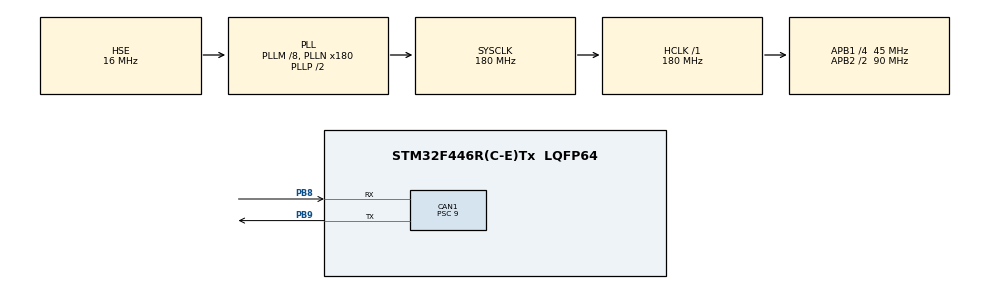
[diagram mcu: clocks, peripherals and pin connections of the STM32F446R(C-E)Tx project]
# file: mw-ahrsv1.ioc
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CAN1.BS1=CAN_BS1_3TQ
CAN1.CalculateBaudRate=1000000
CAN1.CalculateTimeBit=1000.00
CAN1.CalculateTimeQuantum=200.0
CAN1.Prescaler=9
Mcu.Family=STM32F4
Mcu.Name=STM32F446R(C-E)Tx
Mcu.Package=LQFP64
NVIC.CAN1_RX0_IRQn=true\:0\:0\:false\:false\:true\:true\:true
NVIC.PriorityGroup=NVIC_PRIORITYGROUP_4
PA13.Signal=SYS_JTMS-SWDIO
PA14.Signal=SYS_JTCK-SWCLK
PB8.Mode=CAN_Activate
PB8.Signal=CAN1_RX
PB9.Mode=CAN_Activate
PB9.Signal=CAN1_TX
PH0-OSC_IN.Mode=HSE-External-Oscillator
PH0-OSC_IN.Signal=RCC_OSC_IN
PH1-OSC_OUT.Mode=HSE-External-Oscillator
PH1-OSC_OUT.Signal=RCC_OSC_OUT
ProjectManager.HeapSize=0x200
ProjectManager.StackSize=0x400
ProjectManager.TargetToolchain=STM32CubeIDE
RCC.AHBFreq_Value=180000000
RCC.APB1CLKDivider=RCC_HCLK_DIV4
RCC.APB1Freq_Value=45000000
RCC.APB1TimFreq_Value=90000000
RCC.APB2CLKDivider=RCC_HCLK_DIV2
RCC.APB2Freq_Value=90000000
RCC.APB2TimFreq_Value=180000000
RCC.CortexFreq_Value=180000000
RCC.HCLKFreq_Value=180000000
RCC.HSE_VALUE=16000000
RCC.PLLM=8
RCC.PLLN=180
RCC.PLLSourceVirtual=RCC_PLLSOURCE_HSE
RCC.SYSCLKFreq_VALUE=180000000
RCC.SYSCLKSource=RCC_SYSCLKSOURCE_PLLCLK
RCC.USBFreq_Value=180000000
RCC.VCOOutputFreq_Value=360000000
board=custom

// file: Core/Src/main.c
/* USER CODE BEGIN Header */
/**
  ******************************************************************************
  * @file           : main.c
  * @brief          : Main program body
  ******************************************************************************
  * @attention
  *
  * <h2><center>&copy; Copyright (c) 2021 STMicroelectronics.
  * All rights reserved.</center></h2>
  *
  * This software component is licensed by ST under BSD 3-Clause license,
  * the "License"; You may not use this file except in compliance with the
  * License. You may obtain a copy of the License at:
  *                        opensource.org/licenses/BSD-3-Clause
  *
  ******************************************************************************
  */
/* USER CODE END Header */
#include "main.h"
#include "MW-AHRSv1.h"

/* USER CODE BEGIN Includes */
#define AX_WRITE_DATA  3
/* USER CODE END Includes */

/* USER CODE BEGIN PTD */

CAN_RxHeaderTypeDef txheader;
CAN_RxHeaderTypeDef rxheader;

MW_AHRS ahrs_obj = {0, };

/* USER CODE END PTD */

CAN_HandleTypeDef hcan1;

void SystemClock_Config(void);
static void MX_GPIO_Init(void);
static void MX_CAN1_Init(void);
/* USER CODE BEGIN PFP */

void can_init_user(void);
void mw_ahrsv1_trans(void);

uint8_t sendData[100] = { 0, };

float yaw_data;
float roll_data;
float pitch_data;

/* USER CODE END PFP */

int main(void)
{

  /* MCU Configuration--------------------------------------------------------*/

  /* Reset of all peripherals, Initializes the Flash interface and the Systick. */
  HAL_Init();

  /* Configure the system clock */
  SystemClock_Config();

  /* Initialize all configured peripherals */
  MX_GPIO_Init();
  MX_CAN1_Init();
  /* USER CODE BEGIN 2 */

   can_init_user();

   HAL_CAN_ActivateNotification(&hcan1, CAN_IT_TX_MAILBOX_EMPTY | CAN_IT_RX_FIFO0_MSG_PENDING | CAN_IT_RX_FIFO0_FULL);
   HAL_CAN_Start(&hcan1);

   mw_ahrsv1_trans();

  /* USER CODE END 2 */

  /* Infinite loop */
  while (1)
  {

  }
}

void SystemClock_Config(void)
{
  RCC_OscInitTypeDef RCC_OscInitStruct = {0};
  RCC_ClkInitTypeDef RCC_ClkInitStruct = {0};

  /** Configure the main internal regulator output voltage
  */
  __HAL_RCC_PWR_CLK_ENABLE();
  __HAL_PWR_VOLTAGESCALING_CONFIG(PWR_REGULATOR_VOLTAGE_SCALE1);
  /** Initializes the RCC Oscillators according to the specified parameters
  * in the RCC_OscInitTypeDef structure.
  */
  RCC_OscInitStruct.OscillatorType = RCC_OSCILLATORTYPE_HSE;
  RCC_OscInitStruct.HSEState = RCC_HSE_ON;
  RCC_OscInitStruct.PLL.PLLState = RCC_PLL_ON;
  RCC_OscInitStruct.PLL.PLLSource = RCC_PLLSOURCE_HSE;
  RCC_OscInitStruct.PLL.PLLM = 8;
  RCC_OscInitStruct.PLL.PLLN = 180;
  RCC_OscInitStruct.PLL.PLLP = RCC_PLLP_DIV2;
  RCC_OscInitStruct.PLL.PLLQ = 2;
  RCC_OscInitStruct.PLL.PLLR = 2;
  if (HAL_RCC_OscConfig(&RCC_OscInitStruct) != HAL_OK)
  {
    Error_Handler();
  }
  /** Activate the Over-Drive mode
  */
  if (HAL_PWREx_EnableOverDrive() != HAL_OK)
  {
    Error_Handler();
  }
  /** Initializes the CPU, AHB and APB buses clocks
  */
  RCC_ClkInitStruct.ClockType = RCC_CLOCKTYPE_HCLK|RCC_CLOCKTYPE_SYSCLK
                              |RCC_CLOCKTYPE_PCLK1|RCC_CLOCKTYPE_PCLK2;
  RCC_ClkInitStruct.SYSCLKSource = RCC_SYSCLKSOURCE_PLLCLK;
  RCC_ClkInitStruct.AHBCLKDivider = RCC_SYSCLK_DIV1;
  RCC_ClkInitStruct.APB1CLKDivider = RCC_HCLK_DIV4;
  RCC_ClkInitStruct.APB2CLKDivider = RCC_HCLK_DIV2;

  if (HAL_RCC_ClockConfig(&RCC_ClkInitStruct, FLASH_LATENCY_5) != HAL_OK)
  {
    Error_Handler();
  }
}

static void MX_CAN1_Init(void)
{

  hcan1.Instance = CAN1;
  hcan1.Init.Prescaler = 9;
  hcan1.Init.Mode = CAN_MODE_NORMAL;
  hcan1.Init.SyncJumpWidth = CAN_SJW_1TQ;
  hcan1.Init.TimeSeg1 = CAN_BS1_3TQ;
  hcan1.Init.TimeSeg2 = CAN_BS2_1TQ;
  hcan1.Init.TimeTriggeredMode = DISABLE;
  hcan1.Init.AutoBusOff = DISABLE;
  hcan1.Init.AutoWakeUp = DISABLE;
  hcan1.Init.AutoRetransmission = DISABLE;
  hcan1.Init.ReceiveFifoLocked = DISABLE;
  hcan1.Init.TransmitFifoPriority = DISABLE;
  if (HAL_CAN_Init(&hcan1) != HAL_OK)
  {
    Error_Handler();
  }

}

static void MX_GPIO_Init(void)
{

  /* GPIO Ports Clock Enable */
  __HAL_RCC_GPIOH_CLK_ENABLE();
  __HAL_RCC_GPIOA_CLK_ENABLE();
  __HAL_RCC_GPIOB_CLK_ENABLE();

}

/* USER CODE BEGIN 4 */
/////////////////////////////////////////
/////////       begin 4         /////////
/////////////////////////////////////////

void ax12_SetRegister(uint8_t id, uint8_t regstart, uint16_t data) {
	sendData[0] = 0xFF;
	sendData[1] = 0xFF;
	sendData[2] = id;
	sendData[3] = 5;
	sendData[4] = AX_WRITE_DATA;
	sendData[5] = regstart;
	sendData[6] = (data & 0xFF);
	sendData[7] = (data & 0xFF00) >> 8;
	sendData[8] = (0xFF
			- ((id + 5 + AX_WRITE_DATA + regstart + (data & 0xFF)
					+ ((data & 0xFF00) >> 8)) % 256));
}

void can_init_user(void) {

	CAN_FilterTypeDef sFilterConfig;

	sFilterConfig.FilterFIFOAssignment = CAN_FILTER_FIFO0;
	sFilterConfig.FilterMode = CAN_FILTERMODE_IDMASK;
	sFilterConfig.FilterScale = CAN_FILTERSCALE_32BIT;
	sFilterConfig.FilterIdHigh = 0x0000 << 5;
	sFilterConfig.FilterIdLow = 0x0000;
	sFilterConfig.FilterMaskIdHigh = 0x0000 << 5;
	sFilterConfig.FilterMaskIdLow = 0x0000;
	sFilterConfig.SlaveStartFilterBank = 0;
	sFilterConfig.FilterBank = 0;
	sFilterConfig.FilterActivation = CAN_FILTER_ENABLE;

	 HAL_CAN_ConfigFilter(&hcan1, &sFilterConfig);

	if(HAL_CAN_ConfigFilter(&hcan1, &sFilterConfig) != HAL_OK){
		Error_Handler();
	}
}

uint32_t txMailBox;
void mw_ahrsv1_trans(void)
{
	txheader.StdId = 0x01;
	txheader.ExtId = 0x01;
	txheader.RTR = CAN_RTR_DATA;
	txheader.IDE = CAN_ID_STD;
	txheader.DLC = 8;

	mw_ahrs_set_period(&ahrs_obj, 1);
	mw_ahrs_set_data_type(&ahrs_obj, 1, 1, 1, 1);

	txMailBox = HAL_CAN_GetTxMailboxesFreeLevel(&hcan1);
	if (HAL_CAN_AddTxMessage(&hcan1, &txheader, ahrs_obj.can_write_data, &txMailBox)
			!= HAL_OK) {
		Error_Handler();
	}
}

void HAL_CAN_RxFifo0MsgPendingCallback(CAN_HandleTypeDef *hcan) {
	if (hcan->Instance == CAN1) {

		HAL_CAN_GetRxMessage(&hcan1, CAN_RX_FIFO0, &rxheader, ahrs_obj.can_read_data);
		mw_ahrs_input_data(&ahrs_obj);
	}
}
/* USER CODE END 4 */

void Error_Handler(void)
{
  __disable_irq();
  while (1)
  {
  }
}

/************************ (C) COPYRIGHT STMicroelectronics *****END OF FILE****/
